VERSION ""

NS_ :

BS_:

BU_: ADCS_MTQ ADCS_STATEST ADCS_RW_XYZ ADCS_BDot
VAL_TABLE_ MTQCommand 1 "MTQ_Cmd_AssertControl" 0 "MTQ_Cmd_CedeControl" ;
VAL_TABLE_ ReactionWheelCommand 2 "RW_Cmd_OpenLoop" 1 "RW_Cmd_PID" 0 "RW_Cmd_Stop" ;

BO_ 3221225472 VECTOR__INDEPENDENT_SIG_MSG: 0 Vector__XXX
 SG_ CDH_GroupingID : 0|4@1+ (1,0) [0|15] "" Vector__XXX

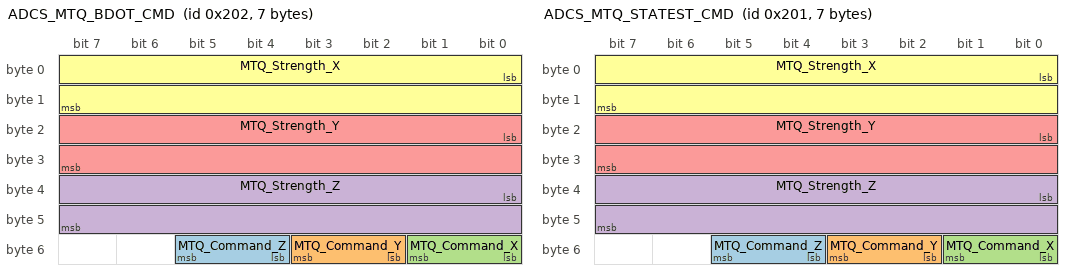
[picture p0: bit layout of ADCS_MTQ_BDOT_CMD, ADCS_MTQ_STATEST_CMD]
BO_ 514 ADCS_MTQ_BDOT_CMD: 7 ADCS_BDot
 SG_ MTQ_Command_Z : 52|2@1+ (1,0) [0|3] ""  ADCS_MTQ
 SG_ MTQ_Command_Y : 50|2@1+ (1,0) [0|3] ""  ADCS_MTQ
 SG_ MTQ_Command_X : 48|2@1+ (1,0) [0|3] ""  ADCS_MTQ
 SG_ MTQ_Strength_Z : 32|16@1- (1,0) [-32768|32767] ""  ADCS_MTQ
 SG_ MTQ_Strength_Y : 16|16@1- (1,0) [-32768|32767] ""  ADCS_MTQ
 SG_ MTQ_Strength_X : 0|16@1- (1,0) [-32768|32767] ""  ADCS_MTQ

BO_ 513 ADCS_MTQ_STATEST_CMD: 7 ADCS_STATEST
 SG_ MTQ_Command_Z : 52|2@1+ (1,0) [0|3] ""  ADCS_MTQ
 SG_ MTQ_Command_Y : 50|2@1+ (1,0) [0|3] ""  ADCS_MTQ
 SG_ MTQ_Command_X : 48|2@1+ (1,0) [0|3] ""  ADCS_MTQ
 SG_ MTQ_Strength_Z : 32|16@1- (1,0) [-32768|32767] ""  ADCS_MTQ
 SG_ MTQ_Strength_Y : 16|16@1- (1,0) [-32768|32767] ""  ADCS_MTQ
 SG_ MTQ_Strength_X : 0|16@1- (1,0) [-32768|32767] ""  ADCS_MTQ

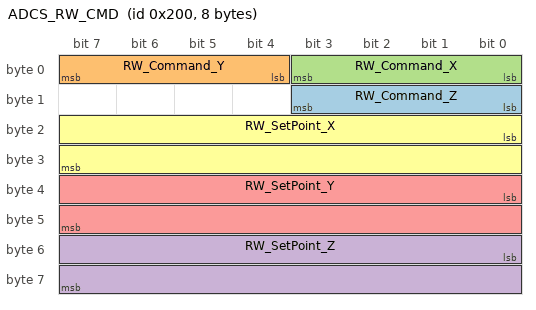
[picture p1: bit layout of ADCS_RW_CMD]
BO_ 512 ADCS_RW_CMD: 8 ADCS_STATEST
 SG_ RW_Command_Z : 8|4@1+ (1,0) [0|3] ""  ADCS_RW_XYZ
 SG_ RW_Command_Y : 4|4@1+ (1,0) [0|3] ""  ADCS_RW_XYZ
 SG_ RW_Command_X : 0|4@1+ (1,0) [0|3] ""  ADCS_RW_XYZ
 SG_ RW_SetPoint_Z : 48|16@1- (1,0) [-32768|32767] "rpm"  ADCS_RW_XYZ
 SG_ RW_SetPoint_Y : 32|16@1- (1,0) [-32768|32767] "rpm"  ADCS_RW_XYZ
 SG_ RW_SetPoint_X : 16|16@1- (1,0) [-32768|32767] "rpm"  ADCS_RW_XYZ

CM_ BO_ 3221225472 "This is a message for not used signals, created by Vector CANdb++ DBC OLE DB Provider.";
BA_DEF_  "BusType" STRING ;
BA_DEF_DEF_  "BusType" "CAN";
VAL_ 514 MTQ_Command_Z 1 "MTQ_Cmd_AssertControl" 0 "MTQ_Cmd_CedeControl" ;
VAL_ 514 MTQ_Command_Y 1 "MTQ_Cmd_AssertControl" 0 "MTQ_Cmd_CedeControl" ;
VAL_ 514 MTQ_Command_X 1 "MTQ_Cmd_AssertControl" 0 "MTQ_Cmd_CedeControl" ;
VAL_ 513 MTQ_Command_Z 1 "MTQ_Cmd_AssertControl" 0 "MTQ_Cmd_CedeControl" ;
VAL_ 513 MTQ_Command_Y 1 "MTQ_Cmd_AssertControl" 0 "MTQ_Cmd_CedeControl" ;
VAL_ 513 MTQ_Command_X 1 "MTQ_Cmd_AssertControl" 0 "MTQ_Cmd_CedeControl" ;
VAL_ 512 RW_Command_Z 2 "RW_Cmd_OpenLoop" 1 "RW_Cmd_PID" 0 "RW_Cmd_Stop" ;
VAL_ 512 RW_Command_Y 2 "RW_Cmd_OpenLoop" 1 "RW_Cmd_PID" 0 "RW_Cmd_Stop" ;
VAL_ 512 RW_Command_X 2 "RW_Cmd_OpenLoop" 1 "RW_Cmd_PID" 0 "RW_Cmd_Stop" ;
